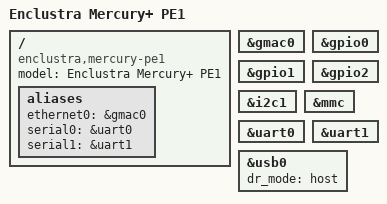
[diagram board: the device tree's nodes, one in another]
// SPDX-License-Identifier: GPL-2.0
/*
 * Copyright 2023 Steffen Trumtrar <kernel@pengutronix.de>
 */
/dts-v1/;
#include "socfpga_arria10_mercury_aa1.dtsi"

/ {
	model = "Enclustra Mercury+ PE1";
	compatible = "enclustra,mercury-pe1", "enclustra,mercury-aa1",
		     "altr,socfpga-arria10", "altr,socfpga";

	aliases {
		ethernet0 = &gmac0;
		serial0 = &uart0;
		serial1 = &uart1;
	};
};

&gmac0 {
	status = "okay";
};

&gpio0 {
	status = "okay";
};

&gpio1 {
	status = "okay";
};

&gpio2 {
	status = "okay";
};

&i2c1 {
	status = "okay";
};

&mmc {
	status = "okay";
};

&uart0 {
	status = "okay";
};

&uart1 {
	status = "okay";
};

&usb0 {
	status = "okay";
	dr_mode = "host";
};
